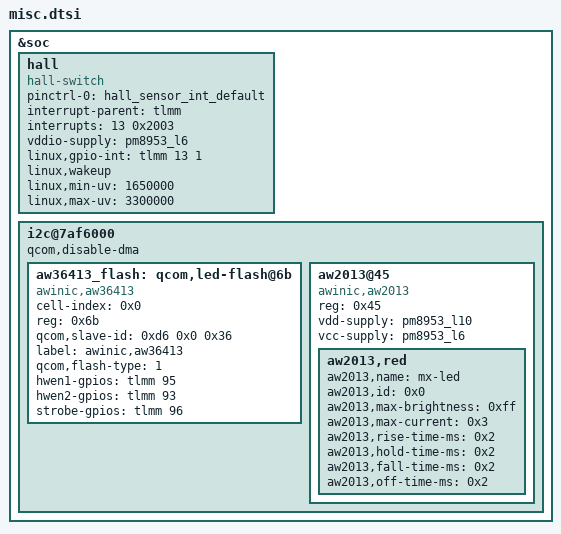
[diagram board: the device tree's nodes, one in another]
/* msm8953-qrd */
&soc {
	hall {
		compatible = "hall-switch";
		pinctrl-names = "default";
		pinctrl-0 = <&hall_sensor_int_default>;
		interrupt-parent = <&tlmm>;
		interrupts = <13 0x2003>;
		vddio-supply = <&pm8953_l6>;
		linux,gpio-int = <&tlmm 13 1>;
		linux,wakeup;
		linux,min-uv = <1650000>;
		linux,max-uv = <3300000>;
	};

	i2c@7af6000 { /* BLSP2 QUP2 */
		status = "ok";
		qcom,disable-dma;

        aw36413_flash: qcom,led-flash@6b {
            cell-index = <0x0>;
            reg = <0x6b>;
            qcom,slave-id = <0xd6 0x0 0x36>;
            compatible = "awinic,aw36413";
            label = "awinic,aw36413";
            qcom,flash-type = <1>;
            hwen1-gpios = <&tlmm 95 0>;
            hwen2-gpios = <&tlmm 93 0>;
            strobe-gpios = <&tlmm 96 0>;
        };
        
        aw2013@45 {
            compatible = "awinic,aw2013";
            reg = <0x45>;
            vdd-supply = <&pm8953_l10>;
            vcc-supply = <&pm8953_l6>;

            aw2013,red {
                aw2013,name = "mx-led";
                aw2013,id = <0x0>;
                aw2013,max-brightness = <0xff>;
                aw2013,max-current = <0x3>;
                aw2013,rise-time-ms = <0x2>;
                aw2013,hold-time-ms = <0x2>;
                aw2013,fall-time-ms = <0x2>;
                aw2013,off-time-ms = <0x2>;
            };
        };
    };
};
